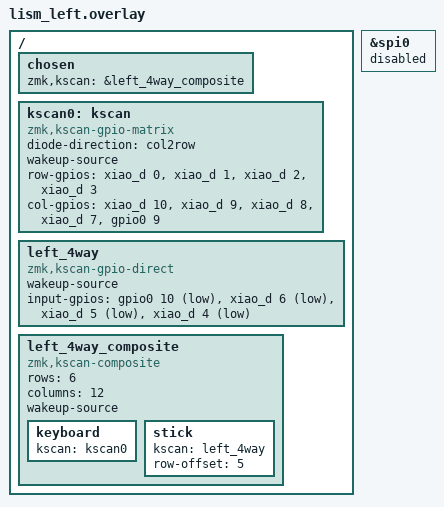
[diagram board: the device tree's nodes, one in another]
#include "lism.dtsi"
#include "lism-layouts.dtsi"

/* No SPI sensor on the left: these four pins are the stock LisM 4waystick. */
&spi0 { status = "disabled"; };

/ {
	chosen {
		zmk,kscan = &left_4way_composite;
	};

	kscan0: kscan {
		compatible = "zmk,kscan-gpio-matrix";
		diode-direction = "col2row";
        wakeup-source;

        row-gpios
            = <&xiao_d 0 (GPIO_ACTIVE_HIGH | GPIO_PULL_DOWN)>   // row0: D0
            , <&xiao_d 1 (GPIO_ACTIVE_HIGH | GPIO_PULL_DOWN)>   // row1: D1
            , <&xiao_d 2 (GPIO_ACTIVE_HIGH | GPIO_PULL_DOWN)>   // row2: D2
            , <&xiao_d 3 (GPIO_ACTIVE_HIGH | GPIO_PULL_DOWN)>   // row3: D3
            ; 

        col-gpios
            = <&xiao_d 10 GPIO_ACTIVE_HIGH>                     // col0: D10
            , <&xiao_d 9  GPIO_ACTIVE_HIGH>                     // col1: D9
            , <&xiao_d 8  GPIO_ACTIVE_HIGH>                     // col2: D8
            , <&xiao_d 7  GPIO_ACTIVE_HIGH>                     // col3: D7
            , <&gpio0  9  GPIO_ACTIVE_HIGH>                     // col4: GPIO9(NFC1)
            ; 
    };

    left_4way: left_4way {
        compatible = "zmk,kscan-gpio-direct";
        wakeup-source;
        /* Up, Right, Down, Left: matches 4mplelab main 8e1fd16 snippets/4waystick.overlay. */
        input-gpios
            = <&gpio0 10 (GPIO_ACTIVE_LOW | GPIO_PULL_UP)>
            , <&xiao_d 6 (GPIO_ACTIVE_LOW | GPIO_PULL_UP)>
            , <&xiao_d 5 (GPIO_ACTIVE_LOW | GPIO_PULL_UP)>
            , <&xiao_d 4 (GPIO_ACTIVE_LOW | GPIO_PULL_UP)>;
    };

    left_4way_composite: left_4way_composite {
        compatible = "zmk,kscan-composite";
        rows = <6>;
        columns = <12>;
        wakeup-source;
        keyboard { kscan = <&kscan0>; };
        stick { kscan = <&left_4way>; row-offset = <5>; };
    };
};
